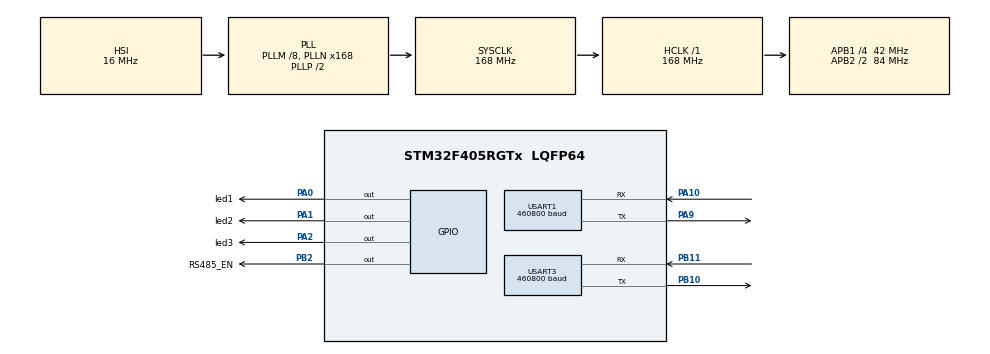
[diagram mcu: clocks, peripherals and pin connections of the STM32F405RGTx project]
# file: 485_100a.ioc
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Dma.Request0=USART3_RX
Dma.Request1=USART3_TX
Dma.Request2=USART1_TX
Dma.Request3=USART1_RX
Dma.USART1_RX.3.Direction=DMA_PERIPH_TO_MEMORY
Dma.USART1_RX.3.FIFOMode=DMA_FIFOMODE_DISABLE
Dma.USART1_RX.3.Instance=DMA2_Stream2
Dma.USART1_RX.3.MemDataAlignment=DMA_MDATAALIGN_BYTE
Dma.USART1_RX.3.MemInc=DMA_MINC_ENABLE
Dma.USART1_RX.3.Mode=DMA_NORMAL
Dma.USART1_RX.3.PeriphDataAlignment=DMA_PDATAALIGN_BYTE
Dma.USART1_RX.3.PeriphInc=DMA_PINC_DISABLE
Dma.USART1_RX.3.Priority=DMA_PRIORITY_LOW
Dma.USART1_TX.2.Direction=DMA_MEMORY_TO_PERIPH
Dma.USART1_TX.2.FIFOMode=DMA_FIFOMODE_DISABLE
Dma.USART1_TX.2.Instance=DMA2_Stream7
Dma.USART1_TX.2.MemDataAlignment=DMA_MDATAALIGN_BYTE
Dma.USART1_TX.2.MemInc=DMA_MINC_ENABLE
Dma.USART1_TX.2.Mode=DMA_NORMAL
Dma.USART1_TX.2.PeriphDataAlignment=DMA_PDATAALIGN_BYTE
Dma.USART1_TX.2.PeriphInc=DMA_PINC_DISABLE
Dma.USART1_TX.2.Priority=DMA_PRIORITY_LOW
Dma.USART3_RX.0.Direction=DMA_PERIPH_TO_MEMORY
Dma.USART3_RX.0.FIFOMode=DMA_FIFOMODE_DISABLE
Dma.USART3_RX.0.Instance=DMA1_Stream1
Dma.USART3_RX.0.MemDataAlignment=DMA_MDATAALIGN_BYTE
Dma.USART3_RX.0.MemInc=DMA_MINC_ENABLE
Dma.USART3_RX.0.Mode=DMA_NORMAL
Dma.USART3_RX.0.PeriphDataAlignment=DMA_PDATAALIGN_BYTE
Dma.USART3_RX.0.PeriphInc=DMA_PINC_DISABLE
Dma.USART3_RX.0.Priority=DMA_PRIORITY_LOW
Dma.USART3_TX.1.Direction=DMA_MEMORY_TO_PERIPH
Dma.USART3_TX.1.FIFOMode=DMA_FIFOMODE_DISABLE
Dma.USART3_TX.1.Instance=DMA1_Stream3
Dma.USART3_TX.1.MemDataAlignment=DMA_MDATAALIGN_BYTE
Dma.USART3_TX.1.MemInc=DMA_MINC_ENABLE
Dma.USART3_TX.1.Mode=DMA_NORMAL
Dma.USART3_TX.1.PeriphDataAlignment=DMA_PDATAALIGN_BYTE
Dma.USART3_TX.1.PeriphInc=DMA_PINC_DISABLE
Dma.USART3_TX.1.Priority=DMA_PRIORITY_LOW
FREERTOS.BinarySemaphores01=ClearYaw,Dynamic,NULL,Depleted;CalcOK,Dynamic,NULL,Depleted;Rxsuccess,Dynamic,NULL,Depleted
FREERTOS.Queues01=ImuQueue,5,7,1,Dynamic,NULL,NULL
FREERTOS.Tasks01=Imu_calc,24,128,ImuCalcTask,As weak,NULL,Dynamic,NULL,NULL;Imu_trans,24,128,ImuTransTask,As weak,NULL,Dynamic,NULL,NULL;State_check,23,128,StateCheckTask,As weak,NULL,Dynamic,NULL,NULL
Mcu.Family=STM32F4
Mcu.Name=STM32F405RGTx
Mcu.Package=LQFP64
NVIC.DMA1_Stream1_IRQn=true\:5\:0\:false\:false\:true\:true\:false\:true\:true
NVIC.DMA1_Stream3_IRQn=true\:5\:0\:false\:false\:true\:true\:false\:true\:true
NVIC.DMA2_Stream2_IRQn=true\:5\:0\:false\:false\:true\:true\:false\:true\:true
NVIC.DMA2_Stream7_IRQn=true\:5\:0\:false\:false\:true\:true\:false\:true\:true
NVIC.PriorityGroup=NVIC_PRIORITYGROUP_4
NVIC.TIM1_UP_TIM10_IRQn=true\:15\:0\:false\:false\:true\:false\:false\:true\:true
NVIC.TimeBase=TIM1_UP_TIM10_IRQn
NVIC.TimeBaseIP=TIM1
NVIC.USART1_IRQn=true\:5\:0\:false\:false\:true\:true\:false\:true\:true
NVIC.USART3_IRQn=true\:5\:0\:false\:false\:true\:true\:false\:true\:true
PA0-WKUP.GPIO_Label=led1
PA0-WKUP.GPIO_PuPd=GPIO_PULLUP
PA0-WKUP.PinState=GPIO_PIN_SET
PA0-WKUP.Signal=GPIO_Output
PA1.GPIO_Label=led2
PA1.GPIO_PuPd=GPIO_PULLUP
PA1.PinState=GPIO_PIN_SET
PA1.Signal=GPIO_Output
PA10.Mode=Asynchronous
PA10.Signal=USART1_RX
PA13.Mode=Serial_Wire
PA13.Signal=SYS_JTMS-SWDIO
PA14.Mode=Serial_Wire
PA14.Signal=SYS_JTCK-SWCLK
PA2.GPIO_Label=led3
PA2.GPIO_PuPd=GPIO_PULLUP
PA2.PinState=GPIO_PIN_SET
PA2.Signal=GPIO_Output
PA9.Mode=Asynchronous
PA9.Signal=USART1_TX
PB10.Mode=Asynchronous
PB10.Signal=USART3_TX
PB11.Mode=Asynchronous
PB11.Signal=USART3_RX
PB2.GPIO_Label=RS485_EN
PB2.GPIO_PuPd=GPIO_PULLDOWN
PB2.GPIO_Speed=GPIO_SPEED_FREQ_HIGH
PB2.Signal=GPIO_Output
PH0-OSC_IN.Mode=HSE-External-Oscillator
PH0-OSC_IN.Signal=RCC_OSC_IN
PH1-OSC_OUT.Mode=HSE-External-Oscillator
PH1-OSC_OUT.Signal=RCC_OSC_OUT
ProjectManager.HeapSize=0x200
ProjectManager.StackSize=0x400
ProjectManager.TargetToolchain=MDK-ARM V5.32
RCC.48MHZClocksFreq_Value=84000000
RCC.AHBFreq_Value=168000000
RCC.APB1CLKDivider=RCC_HCLK_DIV4
RCC.APB1Freq_Value=42000000
RCC.APB1TimFreq_Value=84000000
RCC.APB2CLKDivider=RCC_HCLK_DIV2
RCC.APB2Freq_Value=84000000
RCC.APB2TimFreq_Value=168000000
RCC.CortexFreq_Value=168000000
RCC.HCLKFreq_Value=168000000
RCC.HSE_VALUE=8000000
RCC.HSI_VALUE=16000000
RCC.LSE_VALUE=32768
RCC.PLLM=8
RCC.PLLN=168
RCC.SYSCLKFreq_VALUE=168000000
RCC.SYSCLKSource=RCC_SYSCLKSOURCE_PLLCLK
RCC.VCOOutputFreq_Value=336000000
USART1.BaudRate=460800
USART1.Parity=PARITY_EVEN
USART1.VirtualMode=VM_ASYNC
USART1.WordLength=WORDLENGTH_9B
USART3.BaudRate=460800
USART3.VirtualMode=VM_ASYNC
VP_FREERTOS_VS_CMSIS_V2.Mode=CMSIS_V2
VP_SYS_VS_tim1.Mode=TIM1
board=custom

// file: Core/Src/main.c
/* USER CODE BEGIN Header */
/**
  ******************************************************************************
  * @file           : main.c
  * @brief          : Main program body
  ******************************************************************************
  * @attention
  *
  * Copyright (c) 2026 STMicroelectronics.
  * All rights reserved.
  *
  * This software is licensed under terms that can be found in the LICENSE file
  * in the root directory of this software component.
  * If no LICENSE file comes with this software, it is provided AS-IS.
  *
  ******************************************************************************
  */
/* USER CODE END Header */
#include "main.h"
#include "cmsis_os.h"
#include "dma.h"
#include "usart.h"
#include "gpio.h"

/* USER CODE BEGIN Includes */
#include "mymain.h"
/* USER CODE END Includes */

void SystemClock_Config(void);
void MX_FREERTOS_Init(void);

int main(void)
{

  /* MCU Configuration--------------------------------------------------------*/

  /* Reset of all peripherals, Initializes the Flash interface and the Systick. */
  HAL_Init();

  /* Configure the system clock */
  SystemClock_Config();

  /* Initialize all configured peripherals */
  MX_GPIO_Init();
  MX_DMA_Init();
  MX_USART3_UART_Init();
  MX_USART1_UART_Init();
  /* USER CODE BEGIN 2 */
  Imu_Init();
  /* USER CODE END 2 */

  /* Init scheduler */
  osKernelInitialize();  /* Call init function for freertos objects (in cmsis_os2.c) */
  MX_FREERTOS_Init();

  /* Start scheduler */
  osKernelStart();

  /* We should never get here as control is now taken by the scheduler */

  /* Infinite loop */
  while (1)
  {

  }
}

void SystemClock_Config(void)
{
  RCC_OscInitTypeDef RCC_OscInitStruct = {0};
  RCC_ClkInitTypeDef RCC_ClkInitStruct = {0};

  /** Configure the main internal regulator output voltage
  */
  __HAL_RCC_PWR_CLK_ENABLE();
  __HAL_PWR_VOLTAGESCALING_CONFIG(PWR_REGULATOR_VOLTAGE_SCALE1);

  /** Initializes the RCC Oscillators according to the specified parameters
  * in the RCC_OscInitTypeDef structure.
  */
  RCC_OscInitStruct.OscillatorType = RCC_OSCILLATORTYPE_HSI;
  RCC_OscInitStruct.HSIState = RCC_HSI_ON;
  RCC_OscInitStruct.HSICalibrationValue = RCC_HSICALIBRATION_DEFAULT;
  RCC_OscInitStruct.PLL.PLLState = RCC_PLL_ON;
  RCC_OscInitStruct.PLL.PLLSource = RCC_PLLSOURCE_HSI;
  RCC_OscInitStruct.PLL.PLLM = 8;
  RCC_OscInitStruct.PLL.PLLN = 168;
  RCC_OscInitStruct.PLL.PLLP = RCC_PLLP_DIV2;
  RCC_OscInitStruct.PLL.PLLQ = 4;
  if (HAL_RCC_OscConfig(&RCC_OscInitStruct) != HAL_OK)
  {
    Error_Handler();
  }

  /** Initializes the CPU, AHB and APB buses clocks
  */
  RCC_ClkInitStruct.ClockType = RCC_CLOCKTYPE_HCLK|RCC_CLOCKTYPE_SYSCLK
                              |RCC_CLOCKTYPE_PCLK1|RCC_CLOCKTYPE_PCLK2;
  RCC_ClkInitStruct.SYSCLKSource = RCC_SYSCLKSOURCE_PLLCLK;
  RCC_ClkInitStruct.AHBCLKDivider = RCC_SYSCLK_DIV1;
  RCC_ClkInitStruct.APB1CLKDivider = RCC_HCLK_DIV4;
  RCC_ClkInitStruct.APB2CLKDivider = RCC_HCLK_DIV2;

  if (HAL_RCC_ClockConfig(&RCC_ClkInitStruct, FLASH_LATENCY_5) != HAL_OK)
  {
    Error_Handler();
  }
}

void HAL_TIM_PeriodElapsedCallback(TIM_HandleTypeDef *htim)
{
  if (htim->Instance == TIM1)
  {
    HAL_IncTick();
  }
}

void Error_Handler(void)
{
  __disable_irq();
  while (1)
  {
  }
}

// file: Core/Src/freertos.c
/* USER CODE BEGIN Header */
/**
  ******************************************************************************
  * File Name          : freertos.c
  * Description        : Code for freertos applications
  ******************************************************************************
  * @attention
  *
  * Copyright (c) 2026 STMicroelectronics.
  * All rights reserved.
  *
  * This software is licensed under terms that can be found in the LICENSE file
  * in the root directory of this software component.
  * If no LICENSE file comes with this software, it is provided AS-IS.
  *
  ******************************************************************************
  */
/* USER CODE END Header */

#include "FreeRTOS.h"
#include "task.h"
#include "main.h"
#include "cmsis_os.h"

/* Definitions for Imu_calc */
osThreadId_t Imu_calcHandle;
const osThreadAttr_t Imu_calc_attributes = {
  .name = "Imu_calc",
  .stack_size = 128 * 4,
  .priority = (osPriority_t) osPriorityNormal,
};
/* Definitions for Imu_trans */
osThreadId_t Imu_transHandle;
const osThreadAttr_t Imu_trans_attributes = {
  .name = "Imu_trans",
  .stack_size = 128 * 4,
  .priority = (osPriority_t) osPriorityNormal,
};
/* Definitions for State_check */
osThreadId_t State_checkHandle;
const osThreadAttr_t State_check_attributes = {
  .name = "State_check",
  .stack_size = 128 * 4,
  .priority = (osPriority_t) osPriorityBelowNormal7,
};
/* Definitions for ImuQueue */
osMessageQueueId_t ImuQueueHandle;
const osMessageQueueAttr_t ImuQueue_attributes = {
  .name = "ImuQueue"
};
/* Definitions for ClearYaw */
osSemaphoreId_t ClearYawHandle;
const osSemaphoreAttr_t ClearYaw_attributes = {
  .name = "ClearYaw"
};
/* Definitions for CalcOK */
osSemaphoreId_t CalcOKHandle;
const osSemaphoreAttr_t CalcOK_attributes = {
  .name = "CalcOK"
};
/* Definitions for Rxsuccess */
osSemaphoreId_t RxsuccessHandle;
const osSemaphoreAttr_t Rxsuccess_attributes = {
  .name = "Rxsuccess"
};

void ImuCalcTask(void *argument);
void ImuTransTask(void *argument);
void StateCheckTask(void *argument);

void MX_FREERTOS_Init(void); /* (MISRA C 2004 rule 8.1) */

void MX_FREERTOS_Init(void) {

  /* Create the semaphores(s) */
  /* creation of ClearYaw */
  ClearYawHandle = osSemaphoreNew(1, 0, &ClearYaw_attributes);

  /* creation of CalcOK */
  CalcOKHandle = osSemaphoreNew(1, 0, &CalcOK_attributes);

  /* creation of Rxsuccess */
  RxsuccessHandle = osSemaphoreNew(1, 0, &Rxsuccess_attributes);

  /* Create the queue(s) */
  /* creation of ImuQueue */
  ImuQueueHandle = osMessageQueueNew (5, 7, &ImuQueue_attributes);

  /* Create the thread(s) */
  /* creation of Imu_calc */
  Imu_calcHandle = osThreadNew(ImuCalcTask, NULL, &Imu_calc_attributes);

  /* creation of Imu_trans */
  Imu_transHandle = osThreadNew(ImuTransTask, NULL, &Imu_trans_attributes);

  /* creation of State_check */
  State_checkHandle = osThreadNew(StateCheckTask, NULL, &State_check_attributes);

}

__weak void ImuCalcTask(void *argument)
{
  for(;;)
  {
    osDelay(1);
  }
}

__weak void ImuTransTask(void *argument)
{
  for(;;)
  {
    osDelay(1);
  }
}

__weak void StateCheckTask(void *argument)
{
  for(;;)
  {
    osDelay(1);
  }
}
